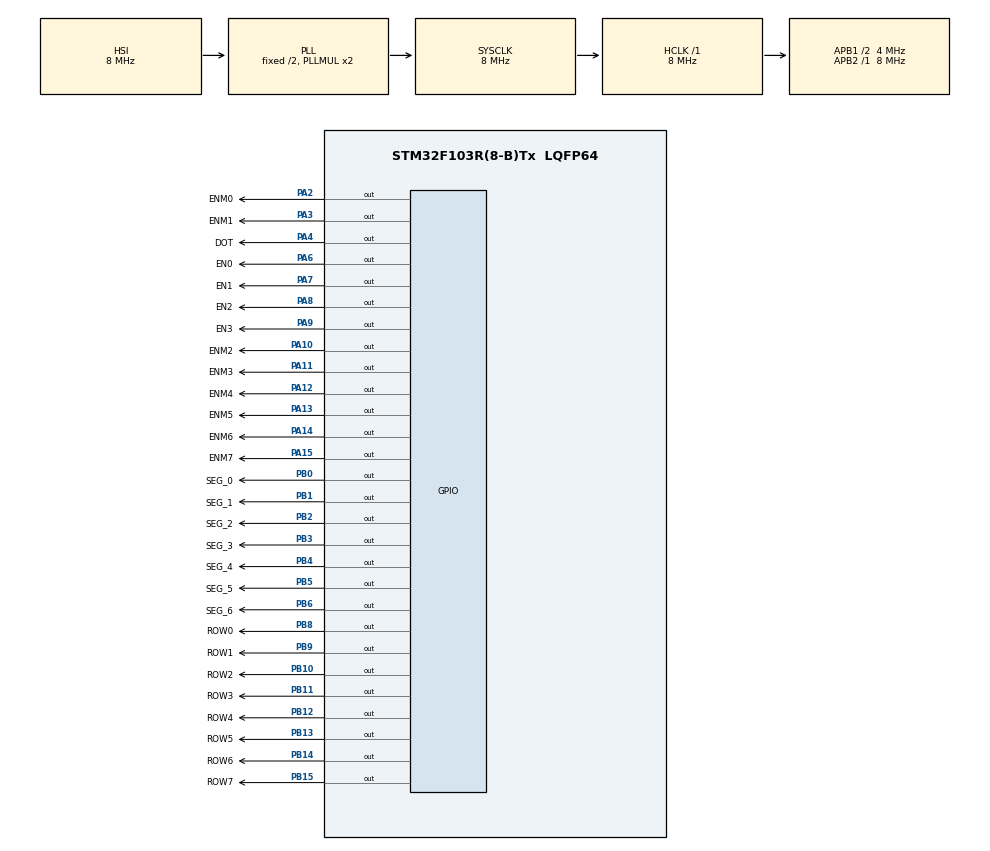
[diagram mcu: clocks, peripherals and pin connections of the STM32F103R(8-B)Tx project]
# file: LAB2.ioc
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Mcu.Family=STM32F1
Mcu.Name=STM32F103R(8-B)Tx
Mcu.Package=LQFP64
NVIC.PriorityGroup=NVIC_PRIORITYGROUP_4
NVIC.TIM2_IRQn=true\:1\:0\:true\:false\:true\:true\:true\:true
PA10.GPIO_Label=ENM2
PA10.Signal=GPIO_Output
PA11.GPIO_Label=ENM3
PA11.Signal=GPIO_Output
PA12.GPIO_Label=ENM4
PA12.Signal=GPIO_Output
PA13.GPIO_Label=ENM5
PA13.Signal=GPIO_Output
PA14.GPIO_Label=ENM6
PA14.Signal=GPIO_Output
PA15.GPIO_Label=ENM7
PA15.Signal=GPIO_Output
PA2.GPIO_Label=ENM0
PA2.Signal=GPIO_Output
PA3.GPIO_Label=ENM1
PA3.Signal=GPIO_Output
PA4.GPIO_Label=DOT
PA4.Signal=GPIO_Output
PA6.GPIO_Label=EN0
PA6.Signal=GPIO_Output
PA7.GPIO_Label=EN1
PA7.Signal=GPIO_Output
PA8.GPIO_Label=EN2
PA8.Signal=GPIO_Output
PA9.GPIO_Label=EN3
PA9.Signal=GPIO_Output
PB0.GPIO_Label=SEG_0
PB0.Signal=GPIO_Output
PB1.GPIO_Label=SEG_1
PB1.Signal=GPIO_Output
PB10.GPIO_Label=ROW2
PB10.Signal=GPIO_Output
PB11.GPIO_Label=ROW3
PB11.Signal=GPIO_Output
PB12.GPIO_Label=ROW4
PB12.Signal=GPIO_Output
PB13.GPIO_Label=ROW5
PB13.Signal=GPIO_Output
PB14.GPIO_Label=ROW6
PB14.Signal=GPIO_Output
PB15.GPIO_Label=ROW7
PB15.Signal=GPIO_Output
PB2.GPIO_Label=SEG_2
PB2.Signal=GPIO_Output
PB3.GPIO_Label=SEG_3
PB3.Signal=GPIO_Output
PB4.GPIO_Label=SEG_4
PB4.Signal=GPIO_Output
PB5.GPIO_Label=SEG_5
PB5.Signal=GPIO_Output
PB6.GPIO_Label=SEG_6
PB6.Signal=GPIO_Output
PB8.GPIO_Label=ROW0
PB8.Signal=GPIO_Output
PB9.GPIO_Label=ROW1
PB9.Signal=GPIO_Output
PC14-OSC32_IN.Signal=RCC_OSC32_IN
PC15-OSC32_OUT.Signal=RCC_OSC32_OUT
PD0-OSC_IN.Signal=RCC_OSC_IN
PD1-OSC_OUT.Signal=RCC_OSC_OUT
ProjectManager.HeapSize=0x200
ProjectManager.StackSize=0x400
ProjectManager.TargetToolchain=STM32CubeIDE
RCC.AHBFreq_Value=8000000
RCC.APB1CLKDivider=RCC_HCLK_DIV2
RCC.APB1Freq_Value=4000000
RCC.APB1TimFreq_Value=8000000
RCC.APB2Freq_Value=8000000
RCC.APB2TimFreq_Value=8000000
RCC.HCLKFreq_Value=8000000
RCC.RTCClockSelection=RCC_RTCCLKSOURCE_LSE
RCC.SYSCLKFreq_VALUE=8000000
RCC.SYSCLKSource=RCC_SYSCLKSOURCE_PLLCLK
RCC.USBFreq_Value=8000000
TIM2.Period=9
TIM2.Prescaler=7999
VP_SYS_VS_ND.Mode=No_Debug
VP_TIM2_VS_ClockSourceINT.Mode=Internal
board=NUCLEO-F103RB

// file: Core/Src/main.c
/* USER CODE BEGIN Header */
/**
  ******************************************************************************
  * @file           : main.c
  * @brief          : Main program body
  ******************************************************************************
  * @attention
  *
  * Copyright (c) 2024 STMicroelectronics.
  * All rights reserved.
  *
  * This software is licensed under terms that can be found in the LICENSE file
  * in the root directory of this software component.
  * If no LICENSE file comes with this software, it is provided AS-IS.
  *
  ******************************************************************************
  */
/* USER CODE END Header */
#include "main.h"

/* USER CODE BEGIN Includes */
#include "ex5.h"
#include "timer.h"
#include "ex10.h"
/* USER CODE END Includes */

TIM_HandleTypeDef htim2;

void SystemClock_Config(void);
static void MX_GPIO_Init(void);
static void MX_TIM2_Init(void);

/* USER CODE BEGIN 0 */
//const int MAX_LED_MATRIX = 8;
//int index_led_matrix = 0;
//uint8_t matrix_buffer[8] = { 0x18, 0x24, 0x42, 0x7E, 0x42, 0x42, 0x42, 0x42 };
//uint16_t ROW_PINS[8] = {
//ROW0_Pin,
//ROW1_Pin,
//ROW2_Pin,
//ROW3_Pin,
//ROW4_Pin,
//ROW5_Pin,
//ROW6_Pin,
//ROW7_Pin };

//void Animation() {
//	for (int shift = 0; shift < 8; shift++) {
//		for (int index = 0; index < MAX_LED_MATRIX; index++) {
//			updateLEDMatrix(index);
//			HAL_Delay(100);
//		}
//
//		// dịch bit sang trái
//		for (int i = 0; i < MAX_LED_MATRIX; i++) {
//			matrix_buffer[i] <<= 1;
//			if (matrix_buffer[i] & 0x80) {
//				matrix_buffer[i] |= 0x01;
//			}
//		}
//	}
//}

void HAL_TIM_PeriodElapsedCallback(TIM_HandleTypeDef *htim) {
	timerRun();
}

/* USER CODE END 0 */

int main(void)
{

  /* MCU Configuration--------------------------------------------------------*/

  /* Reset of all peripherals, Initializes the Flash interface and the Systick. */
  HAL_Init();

  /* Configure the system clock */
  SystemClock_Config();

  /* Initialize all configured peripherals */
  MX_GPIO_Init();
  MX_TIM2_Init();
  /* USER CODE BEGIN 2 */
	HAL_TIM_Base_Start_IT(&htim2);
  /* USER CODE END 2 */

  /* Infinite loop */
  /* USER CODE BEGIN WHILE */
	setTimer1(100);
  while (1)
  {
    /* USER CODE END WHILE */

    /* USER CODE BEGIN 3 */
		Animation();
		//Animation();
  }
  /* USER CODE END 3 */
}

void SystemClock_Config(void)
{
  RCC_OscInitTypeDef RCC_OscInitStruct = {0};
  RCC_ClkInitTypeDef RCC_ClkInitStruct = {0};

  /** Initializes the RCC Oscillators according to the specified parameters
  * in the RCC_OscInitTypeDef structure.
  */
  RCC_OscInitStruct.OscillatorType = RCC_OSCILLATORTYPE_HSI;
  RCC_OscInitStruct.HSIState = RCC_HSI_ON;
  RCC_OscInitStruct.HSICalibrationValue = RCC_HSICALIBRATION_DEFAULT;
  RCC_OscInitStruct.PLL.PLLState = RCC_PLL_ON;
  RCC_OscInitStruct.PLL.PLLSource = RCC_PLLSOURCE_HSI_DIV2;
  RCC_OscInitStruct.PLL.PLLMUL = RCC_PLL_MUL2;
  if (HAL_RCC_OscConfig(&RCC_OscInitStruct) != HAL_OK)
  {
    Error_Handler();
  }

  /** Initializes the CPU, AHB and APB buses clocks
  */
  RCC_ClkInitStruct.ClockType = RCC_CLOCKTYPE_HCLK|RCC_CLOCKTYPE_SYSCLK
                              |RCC_CLOCKTYPE_PCLK1|RCC_CLOCKTYPE_PCLK2;
  RCC_ClkInitStruct.SYSCLKSource = RCC_SYSCLKSOURCE_PLLCLK;
  RCC_ClkInitStruct.AHBCLKDivider = RCC_SYSCLK_DIV1;
  RCC_ClkInitStruct.APB1CLKDivider = RCC_HCLK_DIV2;
  RCC_ClkInitStruct.APB2CLKDivider = RCC_HCLK_DIV1;

  if (HAL_RCC_ClockConfig(&RCC_ClkInitStruct, FLASH_LATENCY_0) != HAL_OK)
  {
    Error_Handler();
  }
}

static void MX_TIM2_Init(void)
{

  TIM_ClockConfigTypeDef sClockSourceConfig = {0};
  TIM_MasterConfigTypeDef sMasterConfig = {0};

  htim2.Instance = TIM2;
  htim2.Init.Prescaler = 7999;
  htim2.Init.CounterMode = TIM_COUNTERMODE_UP;
  htim2.Init.Period = 9;
  htim2.Init.ClockDivision = TIM_CLOCKDIVISION_DIV1;
  htim2.Init.AutoReloadPreload = TIM_AUTORELOAD_PRELOAD_DISABLE;
  if (HAL_TIM_Base_Init(&htim2) != HAL_OK)
  {
    Error_Handler();
  }
  sClockSourceConfig.ClockSource = TIM_CLOCKSOURCE_INTERNAL;
  if (HAL_TIM_ConfigClockSource(&htim2, &sClockSourceConfig) != HAL_OK)
  {
    Error_Handler();
  }
  sMasterConfig.MasterOutputTrigger = TIM_TRGO_RESET;
  sMasterConfig.MasterSlaveMode = TIM_MASTERSLAVEMODE_DISABLE;
  if (HAL_TIMEx_MasterConfigSynchronization(&htim2, &sMasterConfig) != HAL_OK)
  {
    Error_Handler();
  }

}

static void MX_GPIO_Init(void)
{
  GPIO_InitTypeDef GPIO_InitStruct = {0};

  /* GPIO Ports Clock Enable */
  __HAL_RCC_GPIOC_CLK_ENABLE();
  __HAL_RCC_GPIOD_CLK_ENABLE();
  __HAL_RCC_GPIOA_CLK_ENABLE();
  __HAL_RCC_GPIOB_CLK_ENABLE();

  /*Configure GPIO pin Output Level */
  HAL_GPIO_WritePin(GPIOA, ENM0_Pin|ENM1_Pin|DOT_Pin|EN0_Pin
                          |EN1_Pin|EN2_Pin|EN3_Pin|ENM2_Pin
                          |ENM3_Pin|ENM4_Pin|ENM5_Pin|ENM6_Pin
                          |ENM7_Pin, GPIO_PIN_RESET);

  /*Configure GPIO pin Output Level */
  HAL_GPIO_WritePin(GPIOB, SEG_0_Pin|SEG_1_Pin|SEG_2_Pin|ROW2_Pin
                          |ROW3_Pin|ROW4_Pin|ROW5_Pin|ROW6_Pin
                          |ROW7_Pin|SEG_3_Pin|SEG_4_Pin|SEG_5_Pin
                          |SEG_6_Pin|ROW0_Pin|ROW1_Pin, GPIO_PIN_RESET);

  /*Configure GPIO pins : ENM0_Pin ENM1_Pin DOT_Pin EN0_Pin
                           EN1_Pin EN2_Pin EN3_Pin ENM2_Pin
                           ENM3_Pin ENM4_Pin ENM5_Pin ENM6_Pin
                           ENM7_Pin */
  GPIO_InitStruct.Pin = ENM0_Pin|ENM1_Pin|DOT_Pin|EN0_Pin
                          |EN1_Pin|EN2_Pin|EN3_Pin|ENM2_Pin
                          |ENM3_Pin|ENM4_Pin|ENM5_Pin|ENM6_Pin
                          |ENM7_Pin;
  GPIO_InitStruct.Mode = GPIO_MODE_OUTPUT_PP;
  GPIO_InitStruct.Pull = GPIO_NOPULL;
  GPIO_InitStruct.Speed = GPIO_SPEED_FREQ_LOW;
  HAL_GPIO_Init(GPIOA, &GPIO_InitStruct);

  /*Configure GPIO pins : SEG_0_Pin SEG_1_Pin SEG_2_Pin ROW2_Pin
                           ROW3_Pin ROW4_Pin ROW5_Pin ROW6_Pin
                           ROW7_Pin SEG_3_Pin SEG_4_Pin SEG_5_Pin
                           SEG_6_Pin ROW0_Pin ROW1_Pin */
  GPIO_InitStruct.Pin = SEG_0_Pin|SEG_1_Pin|SEG_2_Pin|ROW2_Pin
                          |ROW3_Pin|ROW4_Pin|ROW5_Pin|ROW6_Pin
                          |ROW7_Pin|SEG_3_Pin|SEG_4_Pin|SEG_5_Pin
                          |SEG_6_Pin|ROW0_Pin|ROW1_Pin;
  GPIO_InitStruct.Mode = GPIO_MODE_OUTPUT_PP;
  GPIO_InitStruct.Pull = GPIO_NOPULL;
  GPIO_InitStruct.Speed = GPIO_SPEED_FREQ_LOW;
  HAL_GPIO_Init(GPIOB, &GPIO_InitStruct);

}

void Error_Handler(void)
{
  __disable_irq();
  while (1)
  {
  }
}
